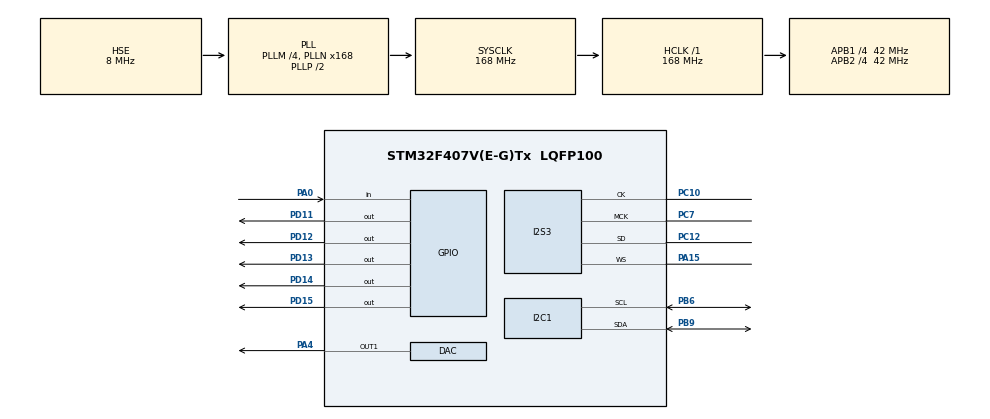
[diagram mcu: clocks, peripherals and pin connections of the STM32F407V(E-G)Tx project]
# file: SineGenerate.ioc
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DAC.DAC_Trigger=DAC_TRIGGER_T6_TRGO
Dma.DAC1.0.Direction=DMA_MEMORY_TO_PERIPH
Dma.DAC1.0.FIFOMode=DMA_FIFOMODE_DISABLE
Dma.DAC1.0.Instance=DMA1_Stream5
Dma.DAC1.0.MemDataAlignment=DMA_MDATAALIGN_BYTE
Dma.DAC1.0.MemInc=DMA_MINC_ENABLE
Dma.DAC1.0.Mode=DMA_CIRCULAR
Dma.DAC1.0.PeriphDataAlignment=DMA_PDATAALIGN_BYTE
Dma.DAC1.0.PeriphInc=DMA_PINC_DISABLE
Dma.DAC1.0.Priority=DMA_PRIORITY_LOW
Dma.Request0=DAC1
Dma.Request1=SPI3_TX
Dma.SPI3_TX.1.Direction=DMA_MEMORY_TO_PERIPH
Dma.SPI3_TX.1.FIFOMode=DMA_FIFOMODE_ENABLE
Dma.SPI3_TX.1.FIFOThreshold=DMA_FIFO_THRESHOLD_FULL
Dma.SPI3_TX.1.Instance=DMA1_Stream7
Dma.SPI3_TX.1.MemBurst=DMA_MBURST_SINGLE
Dma.SPI3_TX.1.MemDataAlignment=DMA_MDATAALIGN_BYTE
Dma.SPI3_TX.1.MemInc=DMA_MINC_ENABLE
Dma.SPI3_TX.1.Mode=DMA_CIRCULAR
Dma.SPI3_TX.1.PeriphBurst=DMA_PBURST_SINGLE
Dma.SPI3_TX.1.PeriphDataAlignment=DMA_PDATAALIGN_BYTE
Dma.SPI3_TX.1.PeriphInc=DMA_PINC_DISABLE
Dma.SPI3_TX.1.Priority=DMA_PRIORITY_LOW
I2S3.AudioFreq=I2S_AUDIOFREQ_48K
I2S3.ErrorAudioFreq=-2.34 %
I2S3.FullDuplexMode=I2S_FULLDUPLEXMODE_DISABLE
I2S3.Instance=SPI$Index
I2S3.RealAudioFreq=46.875 KHz
I2S3.VirtualMode=I2S_MODE_MASTER
Mcu.Family=STM32F4
Mcu.Name=STM32F407V(E-G)Tx
Mcu.Package=LQFP100
NVIC.DMA1_Stream5_IRQn=true\:0\:0\:false\:false\:true\:false\:true
NVIC.DMA1_Stream7_IRQn=true\:0\:0\:false\:false\:true\:false\:true
NVIC.PriorityGroup=NVIC_PRIORITYGROUP_0
NVIC.TIM6_DAC_IRQn=true\:0\:0\:false\:false\:true\:true\:true
PA0-WKUP.Signal=GPIO_Input
PA15.Mode=Half_Duplex_Master
PA15.Signal=I2S3_WS
PA4.Signal=COMP_DAC1_group
PB6.Mode=I2C
PB6.Signal=I2C1_SCL
PB9.Mode=I2C
PB9.Signal=I2C1_SDA
PC10.Mode=Half_Duplex_Master
PC10.Signal=I2S3_CK
PC12.Mode=Half_Duplex_Master
PC12.Signal=I2S3_SD
PC7.Mode=Master_Clock_Activated
PC7.Signal=I2S3_MCK
PD11.Signal=GPIO_Output
PD12.Signal=GPIO_Output
PD13.Signal=GPIO_Output
PD14.Signal=GPIO_Output
PD15.Signal=GPIO_Output
PH0-OSC_IN.Mode=HSE-External-Oscillator
PH0-OSC_IN.Signal=RCC_OSC_IN
PH1-OSC_OUT.Mode=HSE-External-Oscillator
PH1-OSC_OUT.Signal=RCC_OSC_OUT
ProjectManager.HeapSize=0x200
ProjectManager.StackSize=0x400
ProjectManager.TargetToolchain=STM32CubeIDE
RCC.48MHZClocksFreq_Value=48000000
RCC.AHBFreq_Value=168000000
RCC.APB1CLKDivider=RCC_HCLK_DIV4
RCC.APB1Freq_Value=42000000
RCC.APB1TimFreq_Value=84000000
RCC.APB2CLKDivider=RCC_HCLK_DIV4
RCC.APB2Freq_Value=42000000
RCC.APB2TimFreq_Value=84000000
RCC.CortexFreq_Value=168000000
RCC.HCLKFreq_Value=168000000
RCC.HSE_VALUE=8000000
RCC.HSI_VALUE=16000000
RCC.LSE_VALUE=32768
RCC.PLLM=4
RCC.PLLN=168
RCC.PLLQ=7
RCC.PLLSourceVirtual=RCC_PLLSOURCE_HSE
RCC.SYSCLKFreq_VALUE=168000000
RCC.SYSCLKSource=RCC_SYSCLKSOURCE_PLLCLK
RCC.VCOOutputFreq_Value=336000000
SH.COMP_DAC1_group.0=DAC_OUT1,DAC_OUT1
TIM6.Period=20-1
TIM6.Prescaler=84-1
TIM6.TIM_MasterOutputTrigger=TIM_TRGO_UPDATE
VP_TIM6_VS_ClockSourceINT.Mode=Enable_Timer
board=STM32F4DISCOVERY

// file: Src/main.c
/* USER CODE BEGIN Header */
/**
  ******************************************************************************
  * @file           : main.c
  * @brief          : Main program body
  ******************************************************************************
  * @attention
  *
  * <h2><center>&copy; Copyright (c) 2019 STMicroelectronics.
  * All rights reserved.</center></h2>
  *
  * This software component is licensed by ST under Ultimate Liberty license
  * SLA0044, the "License"; You may not use this file except in compliance with
  * the License. You may obtain a copy of the License at:
  *                             www.st.com/SLA0044
  *
  ******************************************************************************
  */

#include "math.h"
/* USER CODE END Header */

#include "main.h"

DAC_HandleTypeDef hdac;
DMA_HandleTypeDef hdma_dac1;

I2C_HandleTypeDef hi2c1;

I2S_HandleTypeDef hi2s3;
DMA_HandleTypeDef hdma_spi3_tx;

TIM_HandleTypeDef htim6;

void SystemClock_Config(void);
static void MX_GPIO_Init(void);
static void MX_DMA_Init(void);
static void MX_DAC_Init(void);
static void MX_TIM6_Init(void);
static void MX_I2C1_Init(void);
static void MX_I2S3_Init(void);

/* USER CODE BEGIN 0 */
#define SAMPLE_SIZE 100
#define PI 3.14159265

/* USER CODE END 0 */

int main(void)
{
  /* USER CODE BEGIN 1 */
	int i = 0;
	double val = 0;

	//const uint8_t signal_DAC[SAMPLE_SIZE] = {0, 40, 80, 120, 160, 120, 80, 40, 0};// -40, -80, -120, -160, -120, -80, -40, 0};

    volatile uint8_t signal_DAC[SAMPLE_SIZE] = {};

	for (i = 0; i < SAMPLE_SIZE; i++)
	{
		val = (PI*i*2)/SAMPLE_SIZE;
		signal_DAC[i] = (uint8_t) (64*sin(val) + 128);
	}

  /* USER CODE END 1 */

  /* MCU Configuration--------------------------------------------------------*/

  /* Reset of all peripherals, Initializes the Flash interface and the Systick. */
  HAL_Init();

  /* Configure the system clock */
  SystemClock_Config();

  /* Initialize all configured peripherals */
  MX_GPIO_Init();
  MX_DMA_Init();
  MX_DAC_Init();
  MX_TIM6_Init();
  MX_I2C1_Init();
  MX_I2S3_Init();
  /* USER CODE BEGIN 2 */

  HAL_TIM_Base_Start(&htim6);
  HAL_I2C_MspDeInit(&hi2c1);
  HAL_I2S_MspInit(&hi2s3);

  HAL_DAC_Start_DMA(&hdac, DAC_CHANNEL_1, (uint32_t *)signal_DAC, SAMPLE_SIZE, DAC_ALIGN_8B_R);
  /* USER CODE END 2 */
  HAL_I2S_Transmit_DMA(&hi2s3, (uint16_t *)signal_DAC , (uint16_t) SAMPLE_SIZE);
  /* Infinite loop */
  while (1)
  {

  }
}

void SystemClock_Config(void)
{
  RCC_OscInitTypeDef RCC_OscInitStruct = {0};
  RCC_ClkInitTypeDef RCC_ClkInitStruct = {0};
  RCC_PeriphCLKInitTypeDef PeriphClkInitStruct = {0};

  /** Configure the main internal regulator output voltage
  */
  __HAL_RCC_PWR_CLK_ENABLE();
  __HAL_PWR_VOLTAGESCALING_CONFIG(PWR_REGULATOR_VOLTAGE_SCALE1);
  /** Initializes the CPU, AHB and APB busses clocks
  */
  RCC_OscInitStruct.OscillatorType = RCC_OSCILLATORTYPE_HSE;
  RCC_OscInitStruct.HSEState = RCC_HSE_ON;
  RCC_OscInitStruct.PLL.PLLState = RCC_PLL_ON;
  RCC_OscInitStruct.PLL.PLLSource = RCC_PLLSOURCE_HSE;
  RCC_OscInitStruct.PLL.PLLM = 4;
  RCC_OscInitStruct.PLL.PLLN = 168;
  RCC_OscInitStruct.PLL.PLLP = RCC_PLLP_DIV2;
  RCC_OscInitStruct.PLL.PLLQ = 7;
  if (HAL_RCC_OscConfig(&RCC_OscInitStruct) != HAL_OK)
  {
    Error_Handler();
  }
  /** Initializes the CPU, AHB and APB busses clocks
  */
  RCC_ClkInitStruct.ClockType = RCC_CLOCKTYPE_HCLK|RCC_CLOCKTYPE_SYSCLK
                              |RCC_CLOCKTYPE_PCLK1|RCC_CLOCKTYPE_PCLK2;
  RCC_ClkInitStruct.SYSCLKSource = RCC_SYSCLKSOURCE_PLLCLK;
  RCC_ClkInitStruct.AHBCLKDivider = RCC_SYSCLK_DIV1;
  RCC_ClkInitStruct.APB1CLKDivider = RCC_HCLK_DIV4;
  RCC_ClkInitStruct.APB2CLKDivider = RCC_HCLK_DIV4;

  if (HAL_RCC_ClockConfig(&RCC_ClkInitStruct, FLASH_LATENCY_5) != HAL_OK)
  {
    Error_Handler();
  }
  PeriphClkInitStruct.PeriphClockSelection = RCC_PERIPHCLK_I2S;
  PeriphClkInitStruct.PLLI2S.PLLI2SN = 192;
  PeriphClkInitStruct.PLLI2S.PLLI2SR = 2;
  if (HAL_RCCEx_PeriphCLKConfig(&PeriphClkInitStruct) != HAL_OK)
  {
    Error_Handler();
  }
}

static void MX_DAC_Init(void)
{

  DAC_ChannelConfTypeDef sConfig = {0};

  /** DAC Initialization
  */
  hdac.Instance = DAC;
  if (HAL_DAC_Init(&hdac) != HAL_OK)
  {
    Error_Handler();
  }
  /** DAC channel OUT1 config
  */
  sConfig.DAC_Trigger = DAC_TRIGGER_T6_TRGO;
  sConfig.DAC_OutputBuffer = DAC_OUTPUTBUFFER_ENABLE;
  if (HAL_DAC_ConfigChannel(&hdac, &sConfig, DAC_CHANNEL_1) != HAL_OK)
  {
    Error_Handler();
  }

}

static void MX_I2C1_Init(void)
{

  hi2c1.Instance = I2C1;
  hi2c1.Init.ClockSpeed = 100000;
  hi2c1.Init.DutyCycle = I2C_DUTYCYCLE_2;
  hi2c1.Init.OwnAddress1 = 0;
  hi2c1.Init.AddressingMode = I2C_ADDRESSINGMODE_7BIT;
  hi2c1.Init.DualAddressMode = I2C_DUALADDRESS_DISABLE;
  hi2c1.Init.OwnAddress2 = 0;
  hi2c1.Init.GeneralCallMode = I2C_GENERALCALL_DISABLE;
  hi2c1.Init.NoStretchMode = I2C_NOSTRETCH_DISABLE;
  if (HAL_I2C_Init(&hi2c1) != HAL_OK)
  {
    Error_Handler();
  }

}

static void MX_I2S3_Init(void)
{

  hi2s3.Instance = SPI3;
  hi2s3.Init.Mode = I2S_MODE_MASTER_TX;
  hi2s3.Init.Standard = I2S_STANDARD_PHILIPS;
  hi2s3.Init.DataFormat = I2S_DATAFORMAT_16B;
  hi2s3.Init.MCLKOutput = I2S_MCLKOUTPUT_ENABLE;
  hi2s3.Init.AudioFreq = I2S_AUDIOFREQ_48K;
  hi2s3.Init.CPOL = I2S_CPOL_LOW;
  hi2s3.Init.ClockSource = I2S_CLOCK_PLL;
  hi2s3.Init.FullDuplexMode = I2S_FULLDUPLEXMODE_DISABLE;
  if (HAL_I2S_Init(&hi2s3) != HAL_OK)
  {
    Error_Handler();
  }

}

static void MX_TIM6_Init(void)
{

  TIM_MasterConfigTypeDef sMasterConfig = {0};

  htim6.Instance = TIM6;
  htim6.Init.Prescaler = 84-1;
  htim6.Init.CounterMode = TIM_COUNTERMODE_UP;
  htim6.Init.Period = 20-1;
  htim6.Init.AutoReloadPreload = TIM_AUTORELOAD_PRELOAD_DISABLE;
  if (HAL_TIM_Base_Init(&htim6) != HAL_OK)
  {
    Error_Handler();
  }
  sMasterConfig.MasterOutputTrigger = TIM_TRGO_UPDATE;
  sMasterConfig.MasterSlaveMode = TIM_MASTERSLAVEMODE_DISABLE;
  if (HAL_TIMEx_MasterConfigSynchronization(&htim6, &sMasterConfig) != HAL_OK)
  {
    Error_Handler();
  }

}

static void MX_DMA_Init(void)
{

  /* DMA controller clock enable */
  __HAL_RCC_DMA1_CLK_ENABLE();

  /* DMA interrupt init */
  /* DMA1_Stream5_IRQn interrupt configuration */
  HAL_NVIC_SetPriority(DMA1_Stream5_IRQn, 0, 0);
  HAL_NVIC_EnableIRQ(DMA1_Stream5_IRQn);
  /* DMA1_Stream7_IRQn interrupt configuration */
  HAL_NVIC_SetPriority(DMA1_Stream7_IRQn, 0, 0);
  HAL_NVIC_EnableIRQ(DMA1_Stream7_IRQn);

}

static void MX_GPIO_Init(void)
{
  GPIO_InitTypeDef GPIO_InitStruct = {0};

  /* GPIO Ports Clock Enable */
  __HAL_RCC_GPIOH_CLK_ENABLE();
  __HAL_RCC_GPIOA_CLK_ENABLE();
  __HAL_RCC_GPIOD_CLK_ENABLE();
  __HAL_RCC_GPIOC_CLK_ENABLE();
  __HAL_RCC_GPIOB_CLK_ENABLE();

  /*Configure GPIO pin Output Level */
  HAL_GPIO_WritePin(GPIOD, GPIO_PIN_11|GPIO_PIN_12|GPIO_PIN_13|GPIO_PIN_14
                          |GPIO_PIN_15, GPIO_PIN_RESET);

  /*Configure GPIO pin : PA0 */
  GPIO_InitStruct.Pin = GPIO_PIN_0;
  GPIO_InitStruct.Mode = GPIO_MODE_INPUT;
  GPIO_InitStruct.Pull = GPIO_NOPULL;
  HAL_GPIO_Init(GPIOA, &GPIO_InitStruct);

  /*Configure GPIO pins : PD11 PD12 PD13 PD14
                           PD15 */
  GPIO_InitStruct.Pin = GPIO_PIN_11|GPIO_PIN_12|GPIO_PIN_13|GPIO_PIN_14
                          |GPIO_PIN_15;
  GPIO_InitStruct.Mode = GPIO_MODE_OUTPUT_PP;
  GPIO_InitStruct.Pull = GPIO_NOPULL;
  GPIO_InitStruct.Speed = GPIO_SPEED_FREQ_LOW;
  HAL_GPIO_Init(GPIOD, &GPIO_InitStruct);

}

void Error_Handler(void)
{
}

/************************ (C) COPYRIGHT STMicroelectronics *****END OF FILE****/
